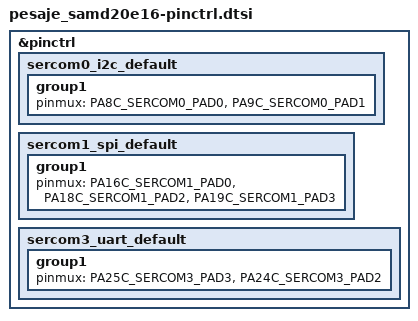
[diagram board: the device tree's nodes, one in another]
/*
 * Copyright (c) 2022, Gerson Fernando Budke <nandojve@gmail.com>
 * SPDX-License-Identifier: Apache-2.0
 */

#include <dt-bindings/pinctrl/samd20jXab-pinctrl.h>

&pinctrl {
	sercom0_i2c_default: sercom0_i2c_default {
		group1 {
			pinmux = <PA8C_SERCOM0_PAD0>,
				 <PA9C_SERCOM0_PAD1>;
		};
	};

	sercom1_spi_default: sercom1_spi_default {
		group1 {
			pinmux = <PA16C_SERCOM1_PAD0>,
				 <PA18C_SERCOM1_PAD2>,
				 <PA19C_SERCOM1_PAD3>;
		};
	};

	sercom3_uart_default: sercom3_uart_default {
		group1 {
			pinmux = <PA25C_SERCOM3_PAD3>,
				 <PA24C_SERCOM3_PAD2>;
		};
	};
};
